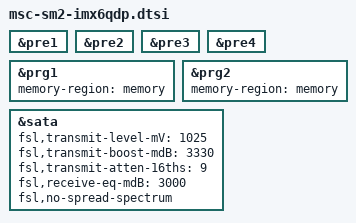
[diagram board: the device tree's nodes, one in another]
/*
 * Copyright 2017 MSC Technologies GmbH 
 *
 * The code contained herein is licensed under the GNU General Public
 * License. You may obtain a copy of the GNU General Public License
 * Version 2 or later at the following locations:
 *
 * http://www.opensource.org/licenses/gpl-license.html
 * http://www.gnu.org/copyleft/gpl.html
 */

#include "imx6qp.dtsi"
#include "msc-sm2-imx6x.dtsi"

&pre1 {
	status = "okay";
};

&pre2 {
	status = "okay";
};

&pre3 {
	status = "okay";
};

&pre4 {
	status = "okay";
};

&prg1 {
	memory-region = <&memory>;
	status = "okay";
};

&prg2 {
	memory-region = <&memory>;
	status = "okay";
};

&sata {
	fsl,transmit-level-mV = <1025>;
	fsl,transmit-boost-mdB = <3330>;
	fsl,transmit-atten-16ths = <9>;
	fsl,receive-eq-mdB = <3000>;
	fsl,no-spread-spectrum;
	status = "okay";
};
